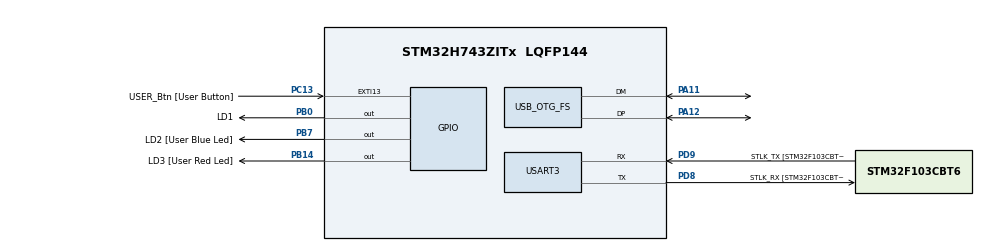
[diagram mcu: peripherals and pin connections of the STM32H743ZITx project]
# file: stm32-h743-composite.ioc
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CORTEX_M7.default_mode_Activation=1
Dma.Request0=USART3_RX
Dma.Request1=USART3_TX
Dma.USART3_RX.0.Direction=DMA_PERIPH_TO_MEMORY
Dma.USART3_RX.0.EventEnable=DISABLE
Dma.USART3_RX.0.FIFOMode=DMA_FIFOMODE_DISABLE
Dma.USART3_RX.0.Instance=DMA1_Stream0
Dma.USART3_RX.0.MemDataAlignment=DMA_MDATAALIGN_BYTE
Dma.USART3_RX.0.MemInc=DMA_MINC_ENABLE
Dma.USART3_RX.0.Mode=DMA_NORMAL
Dma.USART3_RX.0.PeriphDataAlignment=DMA_PDATAALIGN_BYTE
Dma.USART3_RX.0.PeriphInc=DMA_PINC_DISABLE
Dma.USART3_RX.0.Polarity=HAL_DMAMUX_REQ_GEN_RISING
Dma.USART3_RX.0.Priority=DMA_PRIORITY_HIGH
Dma.USART3_RX.0.RequestNumber=1
Dma.USART3_RX.0.SignalID=NONE
Dma.USART3_RX.0.SyncEnable=DISABLE
Dma.USART3_RX.0.SyncPolarity=HAL_DMAMUX_SYNC_NO_EVENT
Dma.USART3_RX.0.SyncRequestNumber=1
Dma.USART3_RX.0.SyncSignalID=NONE
Dma.USART3_TX.1.Direction=DMA_MEMORY_TO_PERIPH
Dma.USART3_TX.1.EventEnable=DISABLE
Dma.USART3_TX.1.FIFOMode=DMA_FIFOMODE_DISABLE
Dma.USART3_TX.1.Instance=DMA1_Stream1
Dma.USART3_TX.1.MemDataAlignment=DMA_MDATAALIGN_BYTE
Dma.USART3_TX.1.MemInc=DMA_MINC_ENABLE
Dma.USART3_TX.1.Mode=DMA_NORMAL
Dma.USART3_TX.1.PeriphDataAlignment=DMA_PDATAALIGN_BYTE
Dma.USART3_TX.1.PeriphInc=DMA_PINC_DISABLE
Dma.USART3_TX.1.Polarity=HAL_DMAMUX_REQ_GEN_RISING
Dma.USART3_TX.1.Priority=DMA_PRIORITY_HIGH
Dma.USART3_TX.1.RequestNumber=1
Dma.USART3_TX.1.SignalID=NONE
Dma.USART3_TX.1.SyncEnable=DISABLE
Dma.USART3_TX.1.SyncPolarity=HAL_DMAMUX_SYNC_NO_EVENT
Dma.USART3_TX.1.SyncRequestNumber=1
Dma.USART3_TX.1.SyncSignalID=NONE
Mcu.Family=STM32H7
Mcu.Name=STM32H743ZITx
Mcu.Package=LQFP144
NVIC.DMA1_Stream0_IRQn=true\:4\:0\:true\:false\:true\:false\:false\:true\:true
NVIC.DMA1_Stream1_IRQn=true\:4\:0\:true\:false\:true\:false\:false\:true\:true
NVIC.OTG_FS_IRQn=true\:7\:0\:true\:false\:true\:false\:true\:true\:true
NVIC.PriorityGroup=NVIC_PRIORITYGROUP_4
NVIC.TIM6_DAC_IRQn=true\:3\:0\:true\:false\:true\:false\:false\:true\:true
NVIC.TimeBase=TIM6_DAC_IRQn
NVIC.TimeBaseIP=TIM6
NVIC.USART3_IRQn=true\:2\:0\:true\:false\:true\:false\:true\:true\:true
PA11.Mode=Device_Only
PA11.Signal=USB_OTG_FS_DM
PA12.Mode=Device_Only
PA12.Signal=USB_OTG_FS_DP
PA13\ (JTMS/SWDIO).GPIO_Label=TMS
PA13\ (JTMS/SWDIO).Mode=Serial_Wire
PA13\ (JTMS/SWDIO).Signal=DEBUG_JTMS-SWDIO
PA14\ (JTCK/SWCLK).GPIO_Label=TCK
PA14\ (JTCK/SWCLK).Mode=Serial_Wire
PA14\ (JTCK/SWCLK).Signal=DEBUG_JTCK-SWCLK
PB0.GPIO_Label=LD1
PB0.Signal=GPIO_Output
PB14.GPIO_Label=LD3 [User Red Led]
PB14.Signal=GPIO_Output
PB7.GPIO_Label=LD2 [User Blue Led]
PB7.Signal=GPIO_Output
PC13.GPIO_Label=USER_Btn [User Button]
PC13.Signal=GPXTI13
PC14-OSC32_IN\ (OSC32_IN).Signal=RCC_OSC32_IN
PC15-OSC32_OUT\ (OSC32_OUT).Signal=RCC_OSC32_OUT
PD8.GPIO_Label=STLK_RX [STM32F103CBT6_PA3]
PD8.Mode=Asynchronous
PD8.Signal=USART3_TX
PD9.GPIO_Label=STLK_TX [STM32F103CBT6_PA2]
PD9.Mode=Asynchronous
PD9.Signal=USART3_RX
PH0-OSC_IN\ (PH0).Mode=HSE-External-Oscillator
PH0-OSC_IN\ (PH0).Signal=RCC_OSC_IN
PH1-OSC_OUT\ (PH1).Mode=HSE-External-Oscillator
PH1-OSC_OUT\ (PH1).Signal=RCC_OSC_OUT
ProjectManager.HeapSize=0x400
ProjectManager.StackSize=0x800
ProjectManager.TargetToolchain=STM32CubeIDE
RCC.48MHZClocksFreq_Value=24000000
RCC.ADCFreq_Value=240000000
RCC.AHBFreq_Value=216000000
RCC.APB1CLKDivider=RCC_HCLK_DIV4
RCC.APB1Freq_Value=120000000
RCC.APB1TimFreq_Value=108000000
RCC.APB2CLKDivider=RCC_HCLK_DIV2
RCC.APB2Freq_Value=120000000
RCC.APB2TimFreq_Value=216000000
RCC.APB3Freq_Value=120000000
RCC.APB4Freq_Value=120000000
RCC.CortexFreq_Value=480000000
RCC.D1PPRE=RCC_APB3_DIV2
RCC.D2PPRE1=RCC_APB1_DIV2
RCC.D2PPRE2=RCC_APB2_DIV2
RCC.D3PPRE=RCC_APB4_DIV2
RCC.DIVM1=4
RCC.DIVM2=4
RCC.DIVM3=4
RCC.DIVN1=480
RCC.DIVN2=240
RCC.DIVN3=240
RCC.DIVQ1=4
RCC.DIVQ2=4
RCC.DIVQ3=10
RCC.HCLKFreq_Value=240000000
RCC.HPRE=RCC_HCLK_DIV2
RCC.HSE_VALUE=8000000
RCC.HSI_VALUE=64000000
RCC.PLLM=25
RCC.PLLMUL=RCC_PLL_MUL9
RCC.PLLN=432
RCC.PLLQ=9
RCC.PRESCALERUSB=RCC_USBCLKSOURCE_PLL_DIV1_5
RCC.PWR_Regulator_Voltage_Scale=PWR_REGULATOR_VOLTAGE_SCALE0
RCC.SYSCLKFreq_VALUE=480000000
RCC.SYSCLKSource=RCC_SYSCLKSOURCE_PLLCLK
RCC.SYSCLKSourceVirtual=RCC_SYSCLKSOURCE_PLLCLK
RCC.USART234578CLockSelection=RCC_USART234578CLKSOURCE_PLL2
RCC.USBCLockSelection=RCC_USBCLKSOURCE_PLL3
RCC.USBFreq_Value=48000000
RCC.VCOOutputFreq_Value=432000000
STMicroelectronics.X-CUBE-AZRTOS-H7.3.3.0.TX_APP_MEM_POOL_SIZE=16*1024
STMicroelectronics.X-CUBE-AZRTOS-H7.3.3.0.TX_MINIMUM_STACK=512
STMicroelectronics.X-CUBE-AZRTOS-H7.3.3.0.ThreadXCcRTOSJjThreadXJjCore=true
STMicroelectronics.X-CUBE-AZRTOS-H7.3.3.0.USBD_CDCACM_EPINCMD_ADDR=3
STMicroelectronics.X-CUBE-AZRTOS-H7.3.3.0.USBD_CDCACM_EPIN_ADDR=2
STMicroelectronics.X-CUBE-AZRTOS-H7.3.3.0.USBD_VIDEO_EPIN_FS_MPS=300
STMicroelectronics.X-CUBE-AZRTOS-H7.3.3.0.USBXCcUSBJjUSBXJjCoreSystem=true
STMicroelectronics.X-CUBE-AZRTOS-H7.3.3.0.USBXCcUSBJjUSBXJjUXOoDeviceOoClassOoCDCOoACM=true
STMicroelectronics.X-CUBE-AZRTOS-H7.3.3.0.USBXCcUSBJjUSBXJjUXOoDeviceOoClassOoVIDEO=true
STMicroelectronics.X-CUBE-AZRTOS-H7.3.3.0.USBXCcUSBJjUSBXJjUXOoDeviceOoControllers=true
STMicroelectronics.X-CUBE-AZRTOS-H7.3.3.0.USBXCcUSBJjUSBXJjUXOoDeviceOoCoreStack=true
STMicroelectronics.X-CUBE-AZRTOS-H7.3.3.0.USBX_DEVICE_SYS_SIZE=12*1024
STMicroelectronics.X-CUBE-AZRTOS-H7.3.3.0.UVC_FRAME_HEIGHT=236
STMicroelectronics.X-CUBE-AZRTOS-H7.3.3.0.UVC_FRAME_WIDTH=320
STMicroelectronics.X-CUBE-AZRTOS-H7.3.3.0.UX_DEVICE_APP_MEM_POOL_SIZE=32*1024
STMicroelectronics.X-CUBE-AZRTOS-H7.3.3.0.UX_MAX_SLAVE_CLASS_DRIVER=2
STMicroelectronics.X-CUBE-AZRTOS-H7.3.3.0.UX_SLAVE_REQUEST_DATA_MAX_LENGTH=512
STMicroelectronics.X-CUBE-AZRTOS-H7.3.3.0_IsAnAzureRtosMw=true
USART3.VirtualMode-Asynchronous=VM_ASYNC
USB_OTG_FS.VirtualMode=Device_Only
VP_CRC_VS_CRC.Mode=CRC_Activate
VP_MEMORYMAP_VS_MEMORYMAP.Mode=CurAppReg
VP_RCC_USB.Mode=USB_FS
VP_RNG_VS_RNG.Mode=RNG_Activate
VP_STMicroelectronics.X-CUBE-AZRTOS-H7_VS_RTOSJjThreadX_6.4.0_3.3.0.Mode=RTOSJjThreadX
VP_STMicroelectronics.X-CUBE-AZRTOS-H7_VS_USBJjUSBX_6.4.0_3.3.0.Mode=USBJjUSBX
VP_SYS_VS_tim6.Mode=TIM6
board=NUCLEO-H743ZI

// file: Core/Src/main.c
/* USER CODE BEGIN Header */
/**
  ******************************************************************************
  * @file           : main.c
  * @brief          : Main program body
  ******************************************************************************
  * @attention
  *
  * Copyright (c) 2025 STMicroelectronics.
  * All rights reserved.
  *
  * This software is licensed under terms that can be found in the LICENSE file
  * in the root directory of this software component.
  * If no LICENSE file comes with this software, it is provided AS-IS.
  *
  ******************************************************************************
  */
/* USER CODE END Header */
#include "app_threadx.h"
#include "main.h"
#include "crc.h"
#include "dma.h"
#include "memorymap.h"
#include "rng.h"
#include "usart.h"
#include "gpio.h"

/* USER CODE BEGIN Includes */
#include "logging.h"
#include "utils.h"

#include <stdio.h>
#include <string.h>
#include <stdbool.h>

/* USER CODE END Includes */

/* USER CODE BEGIN PD */
uint8_t FIRMWARE_VERSION_DATA[3] = {1, 0, 0};

/* USER CODE END PD */

void SystemClock_Config(void);
static void MPU_Config(void);

int main(void)
{

  /* MPU Configuration--------------------------------------------------------*/
  MPU_Config();

  /* MCU Configuration--------------------------------------------------------*/

  /* Reset of all peripherals, Initializes the Flash interface and the Systick. */
  HAL_Init();

  /* Configure the system clock */
  SystemClock_Config();

  /* Initialize all configured peripherals */
  MX_GPIO_Init();
  MX_DMA_Init();
  MX_USART3_UART_Init();
  MX_CRC_Init();
  MX_RNG_Init();
  /* USER CODE BEGIN 2 */
  init_dma_logging();
  printf("\033c");
  printf("Duvitech Example FW v%d.%d.%d\r\n\r\n",FIRMWARE_VERSION_DATA[0], FIRMWARE_VERSION_DATA[1], FIRMWARE_VERSION_DATA[2]);
  printf("CPU Clock Frequency: %lu MHz\r\n", HAL_RCC_GetSysClockFreq() / 1000000);

  /* USER CODE END 2 */

  MX_ThreadX_Init();

  /* We should never get here as control is now taken by the scheduler */

  /* Infinite loop */
  while (1)
  {

  }
}

void SystemClock_Config(void)
{
  RCC_OscInitTypeDef RCC_OscInitStruct = {0};
  RCC_ClkInitTypeDef RCC_ClkInitStruct = {0};
  RCC_CRSInitTypeDef RCC_CRSInitStruct = {0};

  /** Supply configuration update enable
  */
  HAL_PWREx_ConfigSupply(PWR_LDO_SUPPLY);

  /** Configure the main internal regulator output voltage
  */
  __HAL_PWR_VOLTAGESCALING_CONFIG(PWR_REGULATOR_VOLTAGE_SCALE0);

  while(!__HAL_PWR_GET_FLAG(PWR_FLAG_VOSRDY)) {}

  /** Initializes the RCC Oscillators according to the specified parameters
  * in the RCC_OscInitTypeDef structure.
  */
  RCC_OscInitStruct.OscillatorType = RCC_OSCILLATORTYPE_HSI48|RCC_OSCILLATORTYPE_HSE;
  RCC_OscInitStruct.HSEState = RCC_HSE_ON;
  RCC_OscInitStruct.HSI48State = RCC_HSI48_ON;
  RCC_OscInitStruct.PLL.PLLState = RCC_PLL_ON;
  RCC_OscInitStruct.PLL.PLLSource = RCC_PLLSOURCE_HSE;
  RCC_OscInitStruct.PLL.PLLM = 4;
  RCC_OscInitStruct.PLL.PLLN = 480;
  RCC_OscInitStruct.PLL.PLLP = 2;
  RCC_OscInitStruct.PLL.PLLQ = 4;
  RCC_OscInitStruct.PLL.PLLR = 2;
  RCC_OscInitStruct.PLL.PLLRGE = RCC_PLL1VCIRANGE_1;
  RCC_OscInitStruct.PLL.PLLVCOSEL = RCC_PLL1VCOWIDE;
  RCC_OscInitStruct.PLL.PLLFRACN = 0;
  if (HAL_RCC_OscConfig(&RCC_OscInitStruct) != HAL_OK)
  {
    Error_Handler();
  }

  /** Initializes the CPU, AHB and APB buses clocks
  */
  RCC_ClkInitStruct.ClockType = RCC_CLOCKTYPE_HCLK|RCC_CLOCKTYPE_SYSCLK
                              |RCC_CLOCKTYPE_PCLK1|RCC_CLOCKTYPE_PCLK2
                              |RCC_CLOCKTYPE_D3PCLK1|RCC_CLOCKTYPE_D1PCLK1;
  RCC_ClkInitStruct.SYSCLKSource = RCC_SYSCLKSOURCE_PLLCLK;
  RCC_ClkInitStruct.SYSCLKDivider = RCC_SYSCLK_DIV1;
  RCC_ClkInitStruct.AHBCLKDivider = RCC_HCLK_DIV2;
  RCC_ClkInitStruct.APB3CLKDivider = RCC_APB3_DIV2;
  RCC_ClkInitStruct.APB1CLKDivider = RCC_APB1_DIV2;
  RCC_ClkInitStruct.APB2CLKDivider = RCC_APB2_DIV2;
  RCC_ClkInitStruct.APB4CLKDivider = RCC_APB4_DIV2;

  if (HAL_RCC_ClockConfig(&RCC_ClkInitStruct, FLASH_LATENCY_4) != HAL_OK)
  {
    Error_Handler();
  }

  /** Enable the SYSCFG APB clock
  */
  __HAL_RCC_CRS_CLK_ENABLE();

  /** Configures CRS
  */
  RCC_CRSInitStruct.Prescaler = RCC_CRS_SYNC_DIV1;
  RCC_CRSInitStruct.Source = RCC_CRS_SYNC_SOURCE_USB2;
  RCC_CRSInitStruct.Polarity = RCC_CRS_SYNC_POLARITY_RISING;
  RCC_CRSInitStruct.ReloadValue = __HAL_RCC_CRS_RELOADVALUE_CALCULATE(48000000,1000);
  RCC_CRSInitStruct.ErrorLimitValue = 34;
  RCC_CRSInitStruct.HSI48CalibrationValue = 32;

  HAL_RCCEx_CRSConfig(&RCC_CRSInitStruct);
}

 /* MPU Configuration */

void MPU_Config(void)
{
  MPU_Region_InitTypeDef MPU_InitStruct = {0};

  /* Disables the MPU */
  HAL_MPU_Disable();

  /** Initializes and configures the Region and the memory to be protected
  */
  MPU_InitStruct.Enable = MPU_REGION_ENABLE;
  MPU_InitStruct.Number = MPU_REGION_NUMBER0;
  MPU_InitStruct.BaseAddress = 0x0;
  MPU_InitStruct.Size = MPU_REGION_SIZE_4GB;
  MPU_InitStruct.SubRegionDisable = 0x87;
  MPU_InitStruct.TypeExtField = MPU_TEX_LEVEL0;
  MPU_InitStruct.AccessPermission = MPU_REGION_NO_ACCESS;
  MPU_InitStruct.DisableExec = MPU_INSTRUCTION_ACCESS_DISABLE;
  MPU_InitStruct.IsShareable = MPU_ACCESS_SHAREABLE;
  MPU_InitStruct.IsCacheable = MPU_ACCESS_NOT_CACHEABLE;
  MPU_InitStruct.IsBufferable = MPU_ACCESS_NOT_BUFFERABLE;

  HAL_MPU_ConfigRegion(&MPU_InitStruct);
  /* Enables the MPU */
  HAL_MPU_Enable(MPU_PRIVILEGED_DEFAULT);

}

void HAL_TIM_PeriodElapsedCallback(TIM_HandleTypeDef *htim)
{
  if (htim->Instance == TIM6) {
    HAL_IncTick();
  }
}

void Error_Handler(void)
{
  __disable_irq();
  while (1)
  {
  }
}
